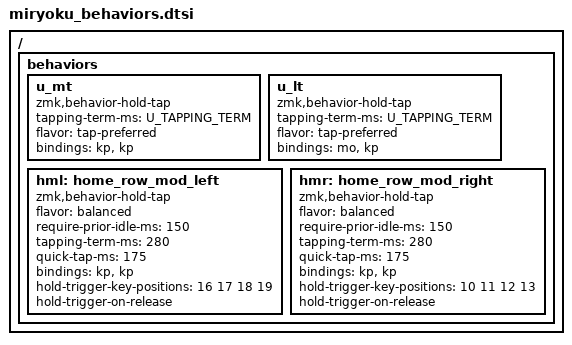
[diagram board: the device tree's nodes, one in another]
// Copyright 2022 Manna Harbour
// https://github.com/manna-harbour/miryoku

/ {
  behaviors {
    u_mt: u_mt {
      compatible = "zmk,behavior-hold-tap";
      #binding-cells = <2>;
      tapping-term-ms = <U_TAPPING_TERM>;
      flavor = "tap-preferred";
      bindings = <&kp>, <&kp>;
    };
    u_lt: u_lt {
      compatible = "zmk,behavior-hold-tap";
      #binding-cells = <2>;
      tapping-term-ms = <U_TAPPING_TERM>;
      flavor = "tap-preferred";
      bindings = <&mo>, <&kp>;
    };
    hml: home_row_mod_left {
      compatible = "zmk,behavior-hold-tap";
      #binding-cells = <2>;
      flavor = "balanced";
      require-prior-idle-ms = <150>;
      tapping-term-ms = <280>;
      quick-tap-ms = <175>;
      bindings = <&kp>, <&kp>;
      hold-trigger-key-positions = <16 17 18 19>;
      hold-trigger-on-release;
    };
    hmr: home_row_mod_right {
      compatible = "zmk,behavior-hold-tap";
      #binding-cells = <2>;
      flavor = "balanced";
      require-prior-idle-ms = <150>;
      tapping-term-ms = <280>;
      quick-tap-ms = <175>;
      bindings = <&kp>, <&kp>;
      hold-trigger-key-positions = <10 11 12 13>;
      hold-trigger-on-release;
    };
  };
};
